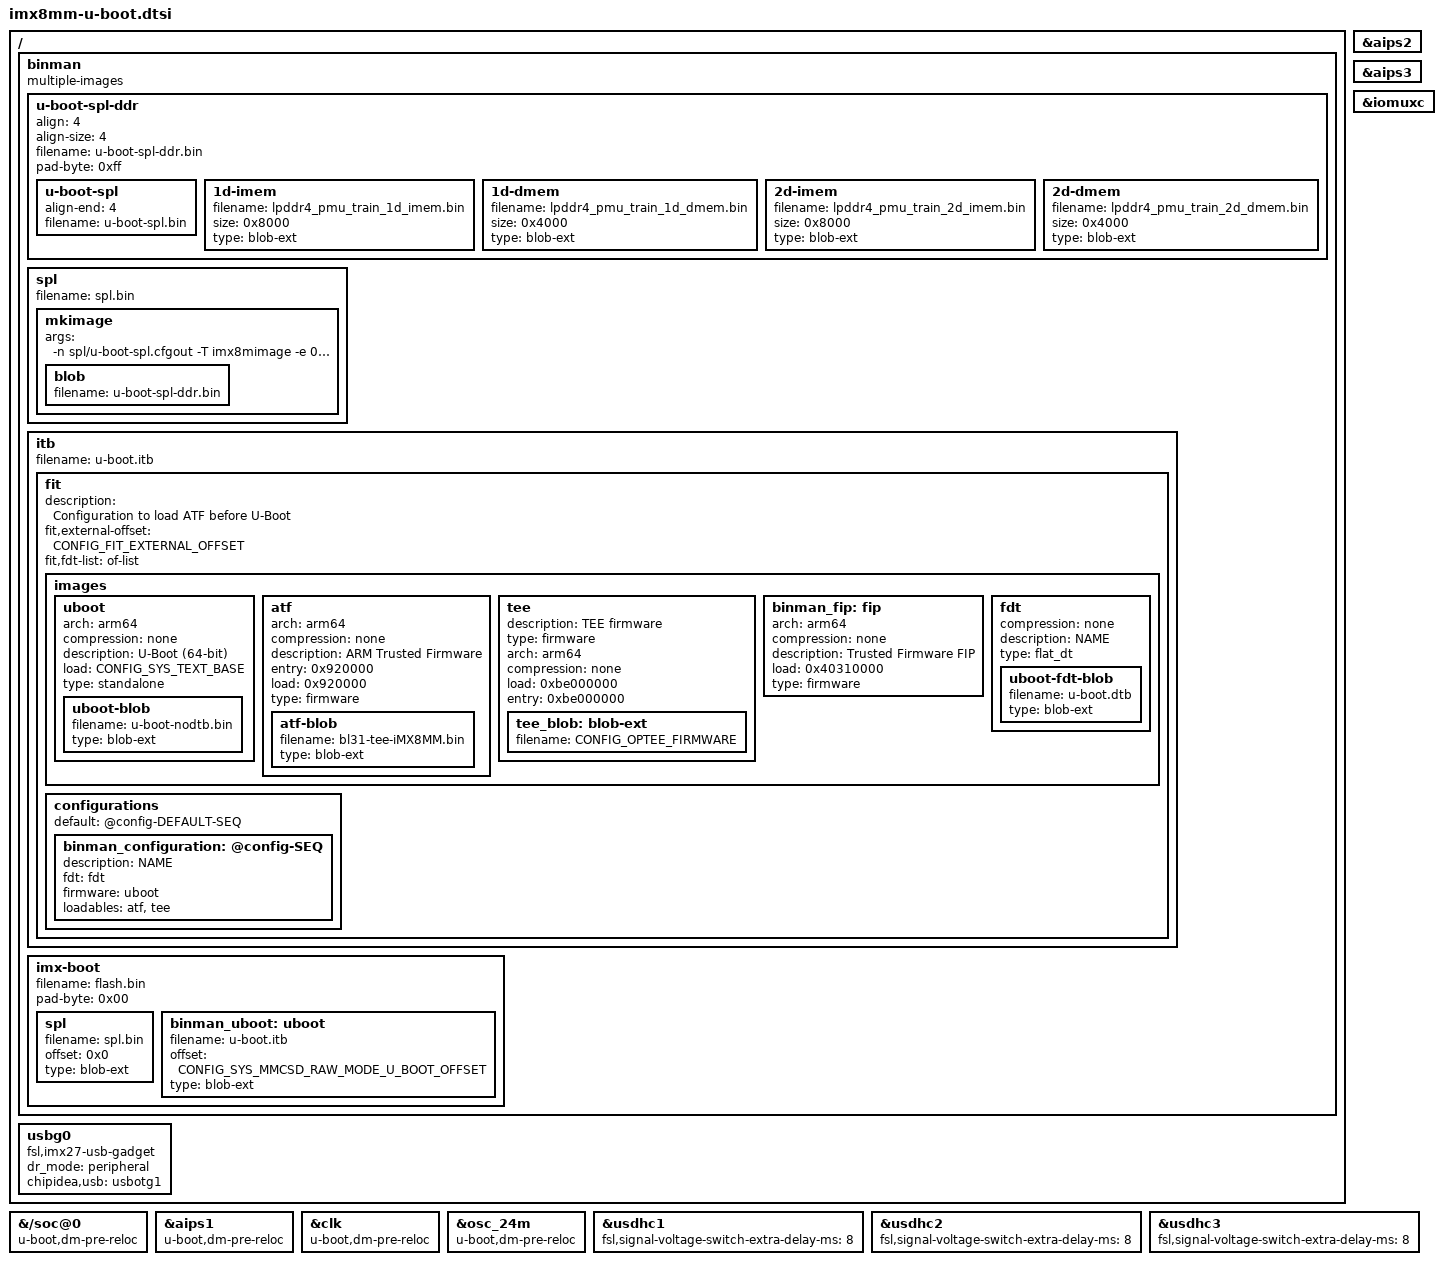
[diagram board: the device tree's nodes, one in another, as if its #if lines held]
// SPDX-License-Identifier: GPL-2.0+
/*
 * Copyright (C) 2020 Jagan Teki <jagan@amarulasolutions.com>
 */

/ {
	binman: binman {
		multiple-images;
	};

	usbg0: usbg0 {
		compatible = "fsl,imx27-usb-gadget";
		dr_mode = "peripheral";
		chipidea,usb = <&usbotg1>;
		status = "okay";
	};
};

&{/soc@0} {
	u-boot,dm-pre-reloc;
	u-boot,dm-spl;
};

&aips1 {
	u-boot,dm-pre-reloc;
	u-boot,dm-spl;
};

&aips2 {
	u-boot,dm-spl;
};

&aips3 {
	u-boot,dm-spl;
};

&binman {
	u-boot-spl-ddr {
		align = <4>;
		align-size = <4>;
		filename = "u-boot-spl-ddr.bin";
		pad-byte = <0xff>;

		u-boot-spl {
			align-end = <4>;
			filename = "u-boot-spl.bin";
		};

		1d-imem {
			filename = "lpddr4_pmu_train_1d_imem.bin";
			size = <0x8000>;
			type = "blob-ext";
		};

		1d-dmem {
			filename = "lpddr4_pmu_train_1d_dmem.bin";
			size = <0x4000>;
			type = "blob-ext";
		};

		2d-imem {
			filename = "lpddr4_pmu_train_2d_imem.bin";
			size = <0x8000>;
			type = "blob-ext";
		};

		2d-dmem {
			filename = "lpddr4_pmu_train_2d_dmem.bin";
			size = <0x4000>;
			type = "blob-ext";
		};
	};

	spl {
		filename = "spl.bin";

		mkimage {
			args = "-n spl/u-boot-spl.cfgout -T imx8mimage -e 0x7e1000";

			blob {
				filename = "u-boot-spl-ddr.bin";
			};
		};
	};

	itb {
		filename = "u-boot.itb";

		fit {
			description = "Configuration to load ATF before U-Boot";
			fit,external-offset = <CONFIG_FIT_EXTERNAL_OFFSET>;
			fit,fdt-list = "of-list";
			#address-cells = <1>;

			images {
				uboot {
					arch = "arm64";
					compression = "none";
					description = "U-Boot (64-bit)";
					load = <CONFIG_SYS_TEXT_BASE>;
					type = "standalone";

					uboot-blob {
						filename = "u-boot-nodtb.bin";
						type = "blob-ext";
					};
				};

				atf {
					arch = "arm64";
					compression = "none";
					description = "ARM Trusted Firmware";
					entry = <0x920000>;
					load = <0x920000>;
					type = "firmware";

					atf-blob {
#ifdef CONFIG_OPTEE_FIRMWARE_SET
						filename = "bl31-tee-iMX8MM.bin";
#else
						filename = "bl31-iMX8MM.bin";
#endif
						type = "blob-ext";
					};
				};

#ifdef CONFIG_OPTEE_FIRMWARE_SET
				tee {
					description = "TEE firmware";
					type = "firmware";
					arch = "arm64";
					compression = "none";
					load = <0xbe000000>;
					entry = <0xbe000000>;

					tee_blob: blob-ext {
						filename = CONFIG_OPTEE_FIRMWARE;
					};
				};
#endif

				binman_fip: fip {
					arch = "arm64";
					compression = "none";
					description = "Trusted Firmware FIP";
					load = <0x40310000>;
					type = "firmware";
				};

				fdt {
					compression = "none";
					description = "NAME";
					type = "flat_dt";

					uboot-fdt-blob {
						filename = "u-boot.dtb";
						type = "blob-ext";
					};
				};
			};

			configurations {
				default = "@config-DEFAULT-SEQ";

				binman_configuration: @config-SEQ {
					description = "NAME";
					fdt = "fdt";
					firmware = "uboot";
#ifdef CONFIG_OPTEE_FIRMWARE_SET
					loadables = "atf", "tee";
#else
					loadables = "atf";
#endif
				};
			};
		};
	};

	imx-boot {
		filename = "flash.bin";
		pad-byte = <0x00>;

		spl {
			filename = "spl.bin";
			offset = <0x0>;
			type = "blob-ext";
		};

		binman_uboot: uboot {
			filename = "u-boot.itb";
#if defined(CONFIG_SYS_MMCSD_RAW_MODE_U_BOOT_USE_OFFSET)
			offset = <CONFIG_SYS_MMCSD_RAW_MODE_U_BOOT_OFFSET>;
#else
			offset = <0x57c00>;
#endif
			type = "blob-ext";
		};
	};
};

&clk {
	u-boot,dm-pre-reloc;
	u-boot,dm-spl;
	/delete-property/ assigned-clocks;
	/delete-property/ assigned-clock-parents;
	/delete-property/ assigned-clock-rates;
};

&iomuxc {
	u-boot,dm-spl;
};

&osc_24m {
	u-boot,dm-pre-reloc;
	u-boot,dm-spl;
};

&usdhc1 {
	fsl,signal-voltage-switch-extra-delay-ms = <8>;
};

&usdhc2 {
	fsl,signal-voltage-switch-extra-delay-ms = <8>;
};

&usdhc3 {
	fsl,signal-voltage-switch-extra-delay-ms = <8>;
};
